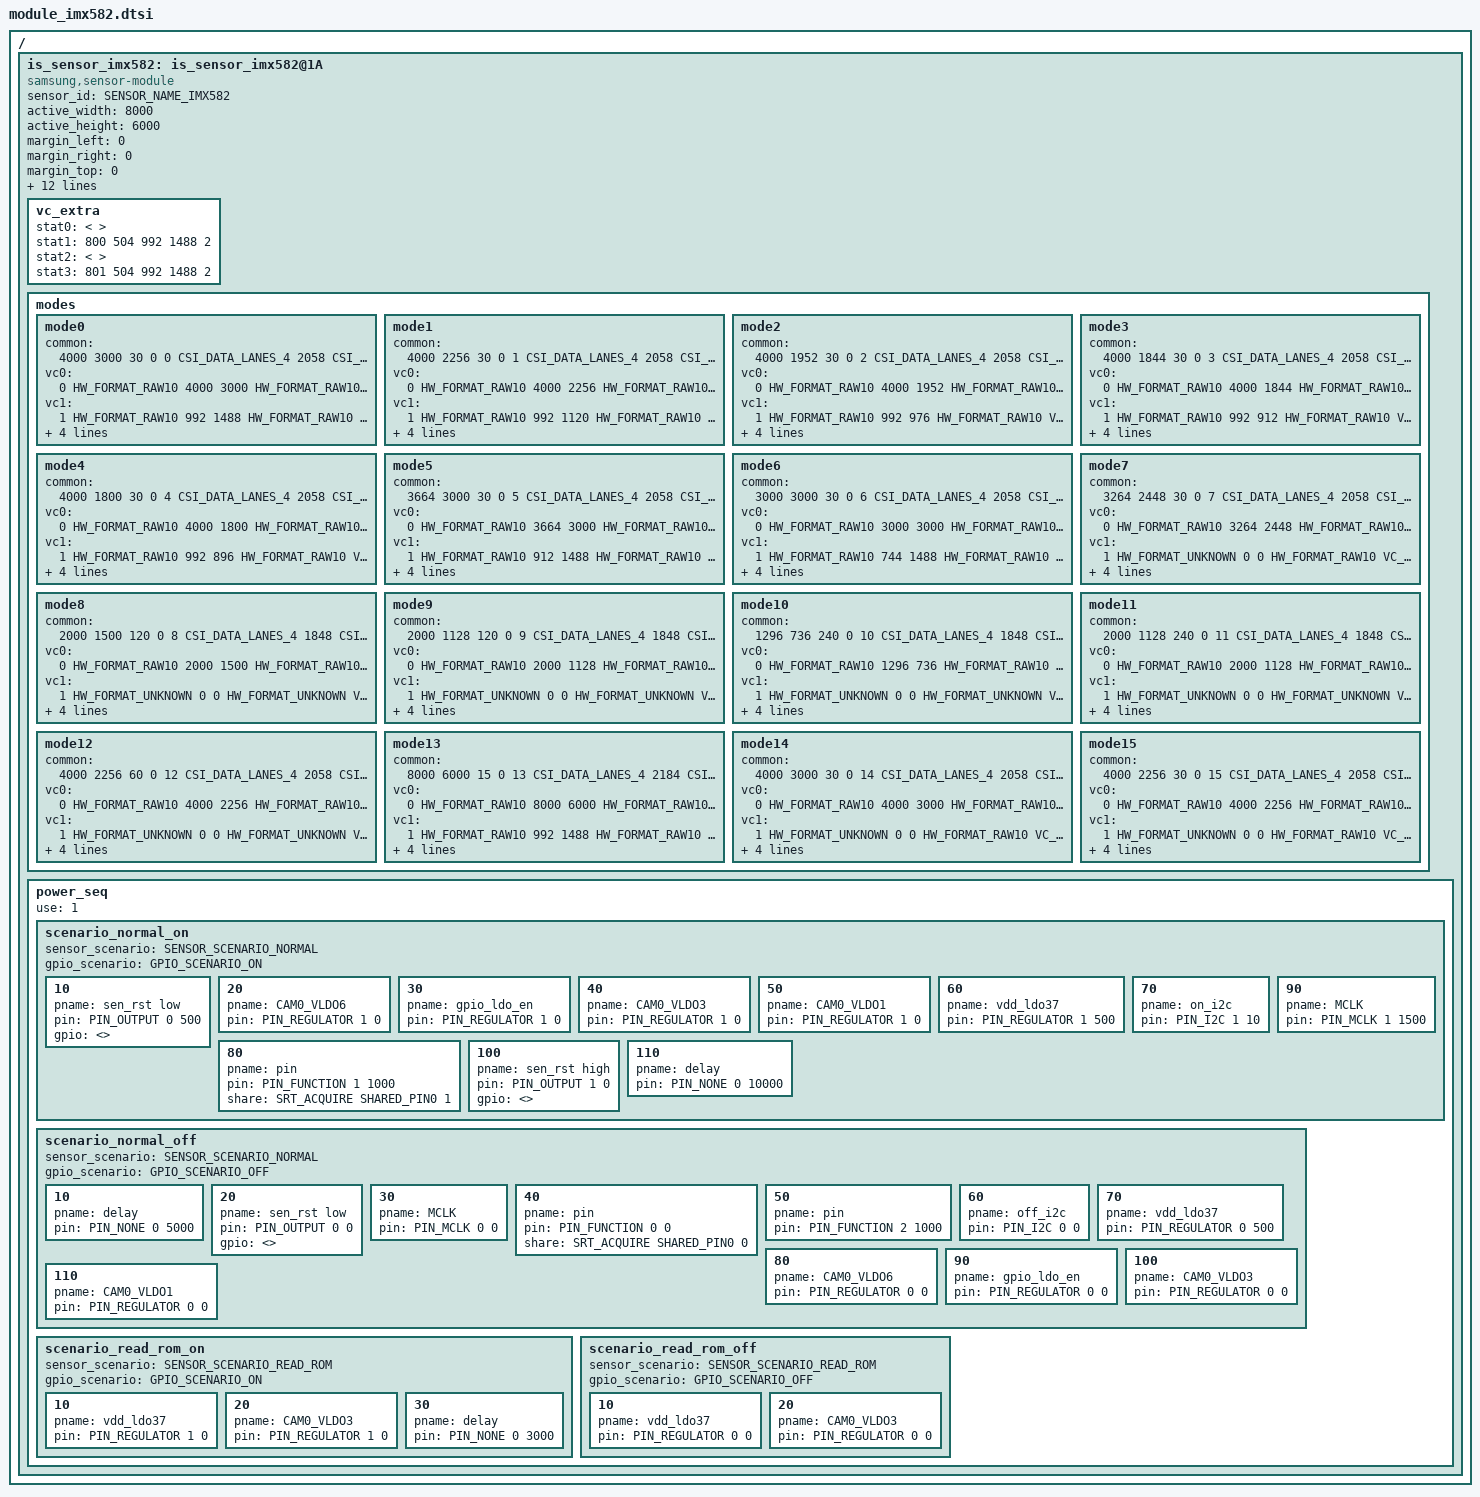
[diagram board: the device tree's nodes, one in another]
/*
 * SAMSUNG EXYNOSxxxx board camera device tree source
 *
 * Copyright (c) 2019 Samsung Electronics Co., Ltd.
 *		http://www.samsung.com
 *
 * This program is free software; you can redistribute it and/or modify
 * it under the terms of the GNU General Public License version 2 as
 * published by the Free Software Foundation.
 */

#include <dt-bindings/camera/exynos_is_dt.h>

/ {
	fragment@camera {
		target-path = "/";
		__overlay__ {
			is_sensor_imx582: is_sensor_imx582@1A {
				compatible = "samsung,sensor-module";

				/* common */
				sensor_id = <SENSOR_NAME_IMX582>;
				active_width = <8000>;
				active_height = <6000>;
				margin_left = <0>;
				margin_right = <0>;
				margin_top = <0>;
				margin_bottom = <0>;
				max_framerate = <247>;
				bitwidth = <10>;
				use_retention_mode = <SENSOR_RETENTION_INACTIVE>;
				sensor_maker = "SONY";
				sensor_name = "IMX582";
				setfile_name = "setfile_imx582.bin";
				rcam_af_vdd-supply = RCAM_AF_VDD;
				imx582_avdd1-supply = IMX582_AVDD1;
				imx582_avdd2-supply = IMX582_AVDD2;
				imx582_dvdd-supply = IMX582_DVDD;
				imx582_iovdd-supply = IMX582_IOVDD;
				status = "okay";

				vc_extra {
					/* ex) statX = <stat_type, sensor_mode, max_width, max_height, max_element> */
					/* VC_BUF_DATA_TYPE_SENSOR_STAT1 */
					stat0 = </* not avaliable */>;
					/* VC_BUF_DATA_TYPE_GENERAL_STAT1 */
					stat1 = </*VC_STAT_TYPE_PDP_1_1_PDAF_STAT0*/ 800 /*VC_SENSOR_MODE_IMX_2X1OCL_2_TAIL*/ 504 992 1488 2>;
					/* VC_BUF_DATA_TYPE_SENSOR_STAT2 */
					stat2 = </* not avaliable */>;
					/* VC_BUF_DATA_TYPE_GENERAL_STAT2 */
					stat3 = </*VC_STAT_TYPE_PDP_1_1_PDAF_STAT1*/ 801 /*VC_SENSOR_MODE_IMX_2X1OCL_2_TAIL*/ 504 992 1488 2>;
				};

				/*
				 * [Mode Information]
				 *
				 * Reference File : IMX582_SEC-DPHY-26MHz_RegisterSetting_ver9.00-5.10_b3_MP0_200508.xlsx
				 * Update Data    : 2020-05-12
				 * Author         : takkyoum.kim
				 *
				 * - Global Setting -
				 *
				 * - 2x2 BIN For Still Preview / Capture -
				 *    [  0 ] REG_H_2_t   : 2x2 Binning Full 4000x3000 30fps    : Single Still Preview/Capture (4:3)    ,  MIPI lane: 4, MIPI data rate(Mbps/lane): 2058
				 *    [  1 ] REG_I_2_t   : 2x2 Binning Crop 4000X2256 30fps    : Single Still Preview/Capture (16:9)   ,  MIPI lane: 4, MIPI data rate(Mbps/lane): 2058
				 *    [  2 ] REG_J_2     : 2x2 Binning Crop 4000X1952 30fps    : Single Still Preview/Capture (18.5:9) ,  MIPI lane: 4, MIPI data rate(Mbps/lane): 2058
				 *    [  3 ] REG_K_2     : 2x2 Binning Crop 4000X1844 30fps    : Single Still Preview/Capture (19.5:9) ,  MIPI lane: 4, MIPI data rate(Mbps/lane): 2058
				 *    [  4 ] REG_L_2     : 2x2 Binning Crop 4000X1800 30fps    : Single Still Preview/Capture (20:9)   ,  MIPI lane: 4, MIPI data rate(Mbps/lane): 2058
				 *    [  5 ] REG_M_2     : 2x2 Binning Crop 3664X3000 30fps    : MMS (11:9)                            ,  MIPI lane: 4, MIPI data rate(Mbps/lane): 2058
				 *    [  6 ] REG_N_2     : 2x2 Binning Crop 3000X3000 30fps    : Single Still Preview/Capture (1:1)    ,  MIPI lane: 4, MIPI data rate(Mbps/lane): 2058
				 *    [  7 ] REG_U       : 2x2 Binning Crop 3264X2448 30fps    : Single Still Capture (4:3)            ,  MIPI lane: 4, MIPI data rate(Mbps/lane): 2058
				 *
				 * - 2x2 BIN V2H2 For HighSpeed Recording/FastAE-
				 *    [  8 ] REG_O_2     : 2x2 Binning V2H2 2000X1500 120fps   : FAST AE (4:3)                         ,  MIPI lane: 4, MIPI data rate(Mbps/lane): 1848
				 *    [  9 ] REG_P_2     : 2x2 Binning V2H2 2000X1128 120fps   : High Speed Recording (16:9)           ,  MIPI lane: 4, MIPI data rate(Mbps/lane): 1848
				 *
				 * - 2x2 BIN V2H2 For HighSpeed Recording -
				 *    [ 10 ] REG_Q_2     : 2x2 Binning V2H2 1296X736  240fps   : High Speed Recording (16:9)           ,  MIPI lane: 4, MIPI data rate(Mbps/lane): 1848
				 *    [ 11 ] REG_R_2     : 2x2 Binning V2H2 2000X1128 240fps   : High Speed Recording (16:9)           ,  MIPI lane: 4, MIPI data rate(Mbps/lane): 1848
				 *
				 * - 2x2 BIN FHD Recording
				 *    [ 12 ] REG_S       : 2x2 Binning V2H2 4000x2256  60fps   : FHD Recording (16:9)                  ,  MIPI lane: 4, MIPI data rate(Mbps/lane): 2058
				 *
				 * - Remosaic For Single Still Remosaic Capture -
				 *    [ 13 ] REG_G       : Remosaic Full 8000x6000 15fps        : Single Still Remosaic Capture (4:3)   ,  MIPI lane: 4, MIPI data rate(Mbps/lane): 2184
				 *    [ 14 ] REG_T_t     : Remosaic Crop 4000x3000 30fps        : Single Still Remosaic Capture (4:3)   ,  MIPI lane: 4, MIPI data rate(Mbps/lane): 2184
				 *    [ 15 ] REG_A_A_t   : Remosaic Crop 4000x2256 30fps        : Single Still Remosaic Capture (16:9)  ,  MIPI lane: 4, MIPI data rate(Mbps/lane): 2058
				 */

				/* sensor modes */
				modes {
						/* common = <width, height, fps, settle, mode, lane, speed, interleave, lrte, pd_mode> */
						/* vcX = <map, hwformat, width, height, hwformat, type, width, height> */

					/* 2x2 BIN For Single Still Preview / Capture */
					mode0 {
						common = <4000 3000 30 0 0 CSI_DATA_LANES_4 2058 CSI_MODE_VC_DT LRTE_DISABLE PD_MSPD_TAIL EX_NONE>;
						vc0 = </* in */ 0 HW_FORMAT_RAW10 4000 3000	/* out */ HW_FORMAT_RAW10 VC_NOTHING 0 0>;
						vc1 = </* in */ 1 HW_FORMAT_RAW10 992 1488	/* out */ HW_FORMAT_RAW10 VC_NOTHING 0 0>;
						vc2 = </* in */ 2 HW_FORMAT_UNKNOWN 0 0		/* out */ HW_FORMAT_RAW10 VC_NOTHING 0 0>;
						vc3 = </* in */ 3 HW_FORMAT_UNKNOWN 0 0		/* out */ HW_FORMAT_RAW10 VC_NOTHING 0 0>;
					};
					mode1 {
						common = <4000 2256 30 0 1 CSI_DATA_LANES_4 2058 CSI_MODE_VC_DT LRTE_DISABLE PD_MSPD_TAIL EX_NONE>;
						vc0 = </* in */ 0 HW_FORMAT_RAW10 4000 2256	/* out */ HW_FORMAT_RAW10 VC_NOTHING 0 0>;
						vc1 = </* in */ 1 HW_FORMAT_RAW10 992 1120	/* out */ HW_FORMAT_RAW10 VC_NOTHING 0 0>;
						vc2 = </* in */ 2 HW_FORMAT_UNKNOWN 0 0		/* out */ HW_FORMAT_RAW10 VC_NOTHING 0 0>;
						vc3 = </* in */ 3 HW_FORMAT_UNKNOWN 0 0		/* out */ HW_FORMAT_RAW10 VC_NOTHING 0 0>;
					};
					mode2 {
						common = <4000 1952 30 0 2 CSI_DATA_LANES_4 2058 CSI_MODE_VC_DT LRTE_DISABLE PD_MSPD_TAIL EX_NONE>;
						vc0 = </* in */ 0 HW_FORMAT_RAW10 4000 1952	/* out */ HW_FORMAT_RAW10 VC_NOTHING 0 0>;
						vc1 = </* in */ 1 HW_FORMAT_RAW10 992 976	/* out */ HW_FORMAT_RAW10 VC_NOTHING 0 0>;
						vc2 = </* in */ 2 HW_FORMAT_UNKNOWN 0 0		/* out */ HW_FORMAT_RAW10 VC_NOTHING 0 0>;
						vc3 = </* in */ 3 HW_FORMAT_UNKNOWN 0 0		/* out */ HW_FORMAT_RAW10 VC_NOTHING 0 0>;
					};
					mode3 {
						common = <4000 1844 30 0 3 CSI_DATA_LANES_4 2058 CSI_MODE_VC_DT LRTE_DISABLE PD_MSPD_TAIL EX_NONE>;
						vc0 = </* in */ 0 HW_FORMAT_RAW10 4000 1844	/* out */ HW_FORMAT_RAW10 VC_NOTHING 0 0>;
						vc1 = </* in */ 1 HW_FORMAT_RAW10 992 912	/* out */ HW_FORMAT_RAW10 VC_NOTHING 0 0>;
						vc2 = </* in */ 2 HW_FORMAT_UNKNOWN 0 0		/* out */ HW_FORMAT_RAW10 VC_NOTHING 0 0>;
						vc3 = </* in */ 3 HW_FORMAT_UNKNOWN 0 0		/* out */ HW_FORMAT_RAW10 VC_NOTHING 0 0>;
					};
					mode4 {
						common = <4000 1800 30 0 4 CSI_DATA_LANES_4 2058 CSI_MODE_VC_DT LRTE_DISABLE PD_MSPD_TAIL EX_NONE>;
						vc0 = </* in */ 0 HW_FORMAT_RAW10 4000 1800	/* out */ HW_FORMAT_RAW10 VC_NOTHING 0 0>;
						vc1 = </* in */ 1 HW_FORMAT_RAW10 992 896	/* out */ HW_FORMAT_RAW10 VC_NOTHING 0 0>;
						vc2 = </* in */ 2 HW_FORMAT_UNKNOWN 0 0		/* out */ HW_FORMAT_RAW10 VC_NOTHING 0 0>;
						vc3 = </* in */ 3 HW_FORMAT_UNKNOWN 0 0		/* out */ HW_FORMAT_RAW10 VC_NOTHING 0 0>;
					};
					mode5 {
						common = <3664 3000 30 0 5 CSI_DATA_LANES_4 2058 CSI_MODE_VC_DT LRTE_DISABLE PD_MSPD_TAIL EX_NONE>;
						vc0 = </* in */ 0 HW_FORMAT_RAW10 3664 3000	/* out */ HW_FORMAT_RAW10 VC_NOTHING 0 0>;
						vc1 = </* in */ 1 HW_FORMAT_RAW10 912 1488	/* out */ HW_FORMAT_RAW10 VC_NOTHING 0 0>;
						vc2 = </* in */ 2 HW_FORMAT_UNKNOWN 0 0		/* out */ HW_FORMAT_RAW10 VC_NOTHING 0 0>;
						vc3 = </* in */ 3 HW_FORMAT_UNKNOWN 0 0		/* out */ HW_FORMAT_RAW10 VC_NOTHING 0 0>;
					};
					mode6 {
						common = <3000 3000 30 0 6 CSI_DATA_LANES_4 2058 CSI_MODE_VC_DT LRTE_DISABLE PD_MSPD_TAIL EX_NONE>;
						vc0 = </* in */ 0 HW_FORMAT_RAW10 3000 3000	/* out */ HW_FORMAT_RAW10 VC_NOTHING 0 0>;
						vc1 = </* in */ 1 HW_FORMAT_RAW10 744 1488	/* out */ HW_FORMAT_RAW10 VC_NOTHING 0 0>;
						vc2 = </* in */ 2 HW_FORMAT_UNKNOWN 0 0		/* out */ HW_FORMAT_RAW10 VC_NOTHING 0 0>;
						vc3 = </* in */ 3 HW_FORMAT_UNKNOWN 0 0		/* out */ HW_FORMAT_RAW10 VC_NOTHING 0 0>;
					};
					mode7 {
						common = <3264 2448 30 0 7 CSI_DATA_LANES_4 2058 CSI_MODE_VC_DT LRTE_DISABLE PD_MSPD_TAIL EX_NONE>;
						vc0 = </* in */ 0 HW_FORMAT_RAW10 3264 2448	/* out */ HW_FORMAT_RAW10 VC_NOTHING 0 0>;
						vc1 = </* in */ 1 HW_FORMAT_UNKNOWN 0 0		/* out */ HW_FORMAT_RAW10 VC_NOTHING 0 0>;
						vc2 = </* in */ 2 HW_FORMAT_UNKNOWN 0 0		/* out */ HW_FORMAT_RAW10 VC_NOTHING 0 0>;
						vc3 = </* in */ 3 HW_FORMAT_UNKNOWN 0 0		/* out */ HW_FORMAT_RAW10 VC_NOTHING 0 0>;
					};
					/* 2x2 BIN V2H2 For HighSpeed Recording/FastAE */
					mode8 {
						common = <2000 1500 120 0 8 CSI_DATA_LANES_4 1848 CSI_MODE_VC_DT LRTE_DISABLE PD_NONE EX_NONE>;
						vc0 = </* in */ 0 HW_FORMAT_RAW10 2000 1500	/* out */ HW_FORMAT_RAW10 VC_NOTHING 0 0>;
						vc1 = </* in */ 1 HW_FORMAT_UNKNOWN 0 0		/* out */ HW_FORMAT_UNKNOWN VC_NOTHING 0 0>;
						vc2 = </* in */ 2 HW_FORMAT_UNKNOWN 0 0		/* out */ HW_FORMAT_UNKNOWN VC_NOTHING 0 0>;
						vc3 = </* in */ 3 HW_FORMAT_UNKNOWN 0 0		/* out */ HW_FORMAT_UNKNOWN VC_NOTHING 0 0>;
					};
					mode9 {
						common = <2000 1128 120 0 9 CSI_DATA_LANES_4 1848 CSI_MODE_VC_DT LRTE_DISABLE PD_NONE EX_NONE>;
						vc0 = </* in */ 0 HW_FORMAT_RAW10 2000 1128	/* out */ HW_FORMAT_RAW10 VC_NOTHING 0 0>;
						vc1 = </* in */ 1 HW_FORMAT_UNKNOWN 0 0		/* out */ HW_FORMAT_UNKNOWN VC_NOTHING 0 0>;
						vc2 = </* in */ 2 HW_FORMAT_UNKNOWN 0 0		/* out */ HW_FORMAT_UNKNOWN VC_NOTHING 0 0>;
						vc3 = </* in */ 3 HW_FORMAT_UNKNOWN 0 0		/* out */ HW_FORMAT_UNKNOWN VC_NOTHING 0 0>;
					};

					/* 2x2 BIN V2H2 For HighSpeed Recording */
					mode10 {
						common = <1296 736 240 0 10 CSI_DATA_LANES_4 1848 CSI_MODE_VC_DT LRTE_DISABLE PD_NONE EX_NONE>;
						vc0 = </* in */ 0 HW_FORMAT_RAW10 1296 736	/* out */ HW_FORMAT_RAW10 VC_NOTHING 0 0>;
						vc1 = </* in */ 1 HW_FORMAT_UNKNOWN 0 0		/* out */ HW_FORMAT_UNKNOWN VC_NOTHING 0 0>;
						vc2 = </* in */ 2 HW_FORMAT_UNKNOWN 0 0		/* out */ HW_FORMAT_UNKNOWN VC_NOTHING 0 0>;
						vc3 = </* in */ 3 HW_FORMAT_UNKNOWN 0 0		/* out */ HW_FORMAT_UNKNOWN VC_NOTHING 0 0>;
					};
					mode11 {
						common = <2000 1128 240 0 11 CSI_DATA_LANES_4 1848 CSI_MODE_VC_DT LRTE_DISABLE PD_NONE EX_NONE>;
						vc0 = </* in */ 0 HW_FORMAT_RAW10 2000 1128	/* out */ HW_FORMAT_RAW10 VC_NOTHING 0 0>;
						vc1 = </* in */ 1 HW_FORMAT_UNKNOWN 0 0		/* out */ HW_FORMAT_UNKNOWN VC_NOTHING 0 0>;
						vc2 = </* in */ 2 HW_FORMAT_UNKNOWN 0 0		/* out */ HW_FORMAT_UNKNOWN VC_NOTHING 0 0>;
						vc3 = </* in */ 3 HW_FORMAT_UNKNOWN 0 0		/* out */ HW_FORMAT_UNKNOWN VC_NOTHING 0 0>;
					};
					mode12 {
						common = <4000 2256 60 0 12 CSI_DATA_LANES_4 2058 CSI_MODE_VC_DT LRTE_DISABLE PD_NONE EX_NONE>;
						vc0 = </* in */ 0 HW_FORMAT_RAW10 4000 2256	/* out */ HW_FORMAT_RAW10 VC_NOTHING 0 0>;
						vc1 = </* in */ 1 HW_FORMAT_UNKNOWN 0 0		/* out */ HW_FORMAT_UNKNOWN VC_NOTHING 0 0>;
						vc2 = </* in */ 2 HW_FORMAT_UNKNOWN 0 0		/* out */ HW_FORMAT_UNKNOWN VC_NOTHING 0 0>;
						vc3 = </* in */ 3 HW_FORMAT_UNKNOWN 0 0		/* out */ HW_FORMAT_UNKNOWN VC_NOTHING 0 0>;
					};
					/* Remosaic Full For Single Still Remosaic Capture */
					mode13 {
						common = <8000 6000 15 0 13 CSI_DATA_LANES_4 2184 CSI_MODE_VC_DT LRTE_DISABLE PD_MSPD_TAIL EX_NONE>;
						vc0 = </* in */ 0 HW_FORMAT_RAW10 8000 6000	/* out */ HW_FORMAT_RAW10 VC_NOTHING 0 0>;
						vc1 = </* in */ 1 HW_FORMAT_RAW10 992 1488	/* out */ HW_FORMAT_RAW10 VC_NOTHING 0 0>;
						vc2 = </* in */ 2 HW_FORMAT_UNKNOWN 0 0		/* out */ HW_FORMAT_RAW10 VC_NOTHING 0 0>;
						vc3 = </* in */ 3 HW_FORMAT_UNKNOWN 0 0		/* out */ HW_FORMAT_RAW10 VC_NOTHING 0 0>;
					};
					mode14 {
						common = <4000 3000 30 0 14 CSI_DATA_LANES_4 2058 CSI_MODE_VC_DT LRTE_DISABLE PD_NONE EX_LOW_RES_TETRA>;
						vc0 = </* in */ 0 HW_FORMAT_RAW10 4000 3000	/* out */ HW_FORMAT_RAW10 VC_NOTHING 0 0>;
						vc1 = </* in */ 1 HW_FORMAT_UNKNOWN 0 0		/* out */ HW_FORMAT_RAW10 VC_NOTHING 0 0>;
						vc2 = </* in */ 2 HW_FORMAT_UNKNOWN 0 0		/* out */ HW_FORMAT_RAW10 VC_NOTHING 0 0>;
						vc3 = </* in */ 3 HW_FORMAT_UNKNOWN 0 0		/* out */ HW_FORMAT_RAW10 VC_NOTHING 0 0>;
					};
					mode15 {
						common = <4000 2256 30 0 15 CSI_DATA_LANES_4 2058 CSI_MODE_VC_DT LRTE_DISABLE PD_NONE EX_LOW_RES_TETRA>;
						vc0 = </* in */ 0 HW_FORMAT_RAW10 4000 2256	/* out */ HW_FORMAT_RAW10 VC_NOTHING 0 0>;
						vc1 = </* in */ 1 HW_FORMAT_UNKNOWN 0 0		/* out */ HW_FORMAT_RAW10 VC_NOTHING 0 0>;
						vc2 = </* in */ 2 HW_FORMAT_UNKNOWN 0 0		/* out */ HW_FORMAT_RAW10 VC_NOTHING 0 0>;
						vc3 = </* in */ 3 HW_FORMAT_UNKNOWN 0 0		/* out */ HW_FORMAT_RAW10 VC_NOTHING 0 0>;
					};
				};

				power_seq {
					use = <1>;
					scenario_normal_on {
						sensor_scenario = <SENSOR_SCENARIO_NORMAL>;
						gpio_scenario = <GPIO_SCENARIO_ON>;

						/* A start node number should be over the 10 for reserved number 0~9. */
						/* pname = "name"; pin = <act value dealy voltage>; gpio = <gpx# # 0x1>; */
						10 { pname = "sen_rst low"; pin = <PIN_OUTPUT 0 500>; gpio = <>; };
						20 { pname = "CAM0_VLDO6"; pin = <PIN_REGULATOR 1 0>; }; /* IMX582_AVDD1 2.9V */
						30 { pname = "gpio_ldo_en"; pin = <PIN_REGULATOR 1 0>; }; /* IMX582_AVDD2 1.8V */
						40 { pname = "CAM0_VLDO3"; pin = <PIN_REGULATOR 1 0>; }; /* IMX582_IOVDD 1.8V */
						50 { pname = "CAM0_VLDO1"; pin = <PIN_REGULATOR 1 0>; }; /* IMX582_DVDD 1.1V */
						60 { pname = "vdd_ldo37"; pin = <PIN_REGULATOR 1 500>; }; /* RCAM_AF_VDD 2.8V */
						70 { pname = "on_i2c"; pin = <PIN_I2C 1 10>; };
						80 { pname = "pin"; pin = <PIN_FUNCTION 1 1000>; share = <SRT_ACQUIRE SHARED_PIN0 1>; };
						90 { pname = "MCLK"; pin = <PIN_MCLK 1 1500>; };
						100 { pname = "sen_rst high"; pin = <PIN_OUTPUT 1 0>; gpio = <>; };
						110 { pname = "delay"; pin = <PIN_NONE 0 10000>; };
					};

					scenario_normal_off {
						sensor_scenario = <SENSOR_SCENARIO_NORMAL>;
						gpio_scenario = <GPIO_SCENARIO_OFF>;

						/* A start node number should be over the 10 for reserved number 0~9. */
						/* pname = "name"; pin = <act value dealy voltage>; gpio = <gpx# # 0x1>; */
						10 { pname = "delay"; pin = <PIN_NONE 0 5000>; };
						20 { pname = "sen_rst low"; pin = <PIN_OUTPUT 0 0>; gpio = <>; };
						30 { pname = "MCLK"; pin = <PIN_MCLK 0 0>; };
						40 { pname = "pin"; pin = <PIN_FUNCTION 0 0>; share = <SRT_ACQUIRE SHARED_PIN0 0>; };
						50 { pname = "pin"; pin = <PIN_FUNCTION 2 1000>; };
						60 { pname = "off_i2c"; pin = <PIN_I2C 0 0>; };
						70 { pname = "vdd_ldo37"; pin = <PIN_REGULATOR 0 500>; }; /* RCAM_AF_VDD 2.8V */
						80 { pname = "CAM0_VLDO6"; pin = <PIN_REGULATOR 0 0>; }; /* IMX582_AVDD1 2.9V */
						90 { pname = "gpio_ldo_en"; pin = <PIN_REGULATOR 0 0>; }; /* IMX582_AVDD2 1.8V */
						100 { pname = "CAM0_VLDO3"; pin = <PIN_REGULATOR 0 0>; }; /* IMX582_IOVDD 1.8V */
						110 { pname = "CAM0_VLDO1"; pin = <PIN_REGULATOR 0 0>; }; /* IMX582_DVDD 1.1V */
					};

					scenario_read_rom_on {
						sensor_scenario = <SENSOR_SCENARIO_READ_ROM>;
						gpio_scenario = <GPIO_SCENARIO_ON>;

						/* A start node number should be over the 10 for reserved number 0~9. */
						/* pname = "name"; pin = <act value dealy voltage>; gpio = <gpx# # 0x1>; */
						10 { pname = "vdd_ldo37"; pin = <PIN_REGULATOR 1 0>; }; /* RCAM_AF_VDD 2.8V */
						20 { pname = "CAM0_VLDO3"; pin = <PIN_REGULATOR 1 0>; }; /* IMX582_IOVDD 1.8V */
						30 { pname = "delay"; pin = <PIN_NONE 0 3000>; };
					};

					scenario_read_rom_off {
						sensor_scenario = <SENSOR_SCENARIO_READ_ROM>;
						gpio_scenario = <GPIO_SCENARIO_OFF>;

						/* A start node number should be over the 10 for reserved number 0~9. */
						/* pname = "name"; pin = <act value dealy voltage>; gpio = <gpx# # 0x1>; */
						10 { pname = "vdd_ldo37"; pin = <PIN_REGULATOR 0 0>; }; /* RCAM_AF_VDD 2.8V */
						20 { pname = "CAM0_VLDO3"; pin = <PIN_REGULATOR 0 0>; }; /* IMX582_IOVDD 1.8V */
					};
				};
			};
		}; /* end of __overlay__ */
	}; /* end of fragment */
}; /* end of root */
